# APM32L08x register map
File version: 1.0
CPU: CM0+ r0p0, little endian, MPU, no FPU, 4 interrupt priority bits
Registers are 32-bit, read-write, reset 0x0 unless marked. A register's access mark holds for its fields unless they carry their own. Offsets are from the block's base; [hi:lo] are bit positions; lines under a group give offsets from that group; {n}, {i} and the like mark numbered series.

## WWDT — Window watchdog
Base 0x40002C00
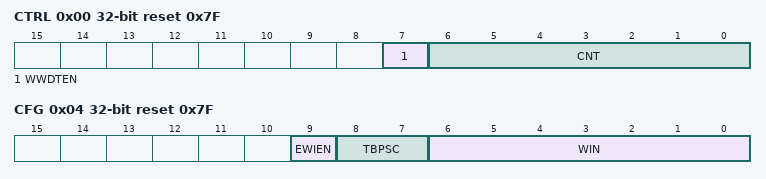
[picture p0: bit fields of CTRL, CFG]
0x00 CTRL reset 0x7F — Control register
  [7] WWDTEN — Activation bit
  [6:0] CNT — 7-bit counter
0x04 CFG reset 0x7F — Configuration register
  [9] EWIEN — Early wakeup interrupt
  [8:7] TBPSC — Timer base
  [6:0] WIN — 7-bit window value
0x08 STS — Status register
  [0] EWIFLG — Early wakeup interrupt flag

## TSC — Touch sensing controller
Base 0x40024000
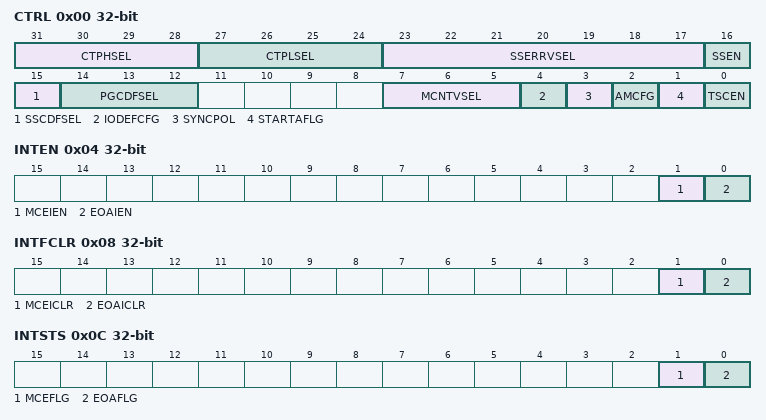
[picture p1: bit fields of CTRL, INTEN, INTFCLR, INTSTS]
0x00 CTRL — control register
  [31:28] CTPHSEL — Charge transfer pulse high
  [27:24] CTPLSEL — Charge transfer pulse low
  [23:17] SSERRVSEL — Spread spectrum deviation
  [16] SSEN — Spread spectrum enable
  [15] SSCDFSEL — Spread spectrum prescaler
  [14:12] PGCDFSEL — pulse generator prescaler
  [7:5] MCNTVSEL — Max count error value
  [4] IODEFCFG — I/O Default mode
  [3] SYNCPOL — Synchronization pin polarity
  [2] AMCFG — Acquisition mode
  [1] STARTAFLG — Start a new acquisition
  [0] TSCEN — Touch sensing controller enable
0x04 INTEN — interrupt enable register
  [1] MCEIEN — Max count error interrupt enable
  [0] EOAIEN — End of acquisition interrupt enable
0x08 INTFCLR — interrupt clear register
  [1] MCEICLR — Max count error interrupt clear
  [0] EOAICLR — End of acquisition interrupt clear
0x0C INTSTS ro — interrupt status register
  [1] MCEFLG — Max count error flag
  [0] EOAFLG — End of acquisition flag
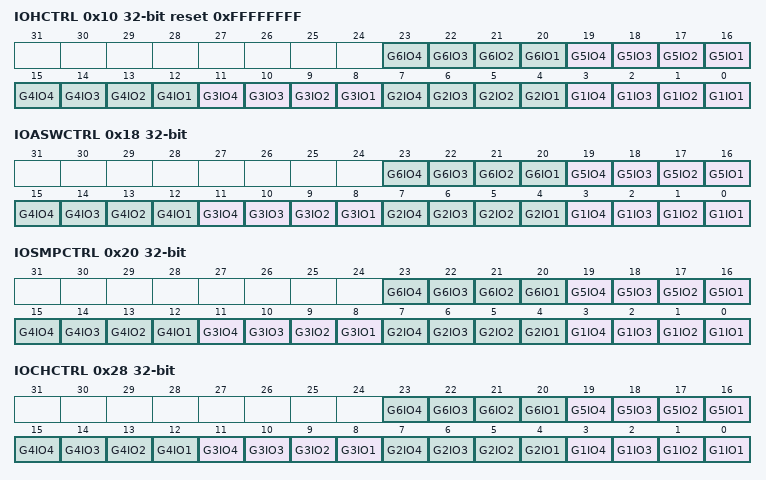
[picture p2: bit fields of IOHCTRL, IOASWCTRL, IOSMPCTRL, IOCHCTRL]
0x10 IOHCTRL reset 0xFFFFFFFF — I/O hysteresis control register
  [4n-1] G{n}IO4 (n=1..6) — G{n}IO4 Schmitt trigger hysteresis mode
  [4n-2] G{n}IO3 (n=1..6) — G{n}IO3 Schmitt trigger hysteresis mode
  [4n-3] G{n}IO2 (n=1..6) — G{n}IO2 Schmitt trigger hysteresis mode
  [4n-4] G{n}IO1 (n=1..6) — G{n}IO1 Schmitt trigger hysteresis mode
0x18 IOASWCTRL — I/O analog switch control register
  [4n-1] G{n}IO4 (n=1..6) — G{n}IO4 analog switch enable
  [4n-2] G{n}IO3 (n=1..6) — G{n}IO3 analog switch enable
  [4n-3] G{n}IO2 (n=1..6) — G{n}IO2 analog switch enable
  [4n-4] G{n}IO1 (n=1..6) — G{n}IO1 analog switch enable
0x20 IOSMPCTRL — I/O sampling control register
  [4n-1] G{n}IO4 (n=1..6) — G{n}IO4 sampling mode
  [4n-2] G{n}IO3 (n=1..6) — G{n}IO3 sampling mode
  [4n-3] G{n}IO2 (n=1..6) — G{n}IO2 sampling mode
  [4n-4] G{n}IO1 (n=1..6) — G{n}IO1 sampling mode
0x28 IOCHCTRL — I/O channel control register
  [4n-1] G{n}IO4 (n=1..6) — G{n}IO4 channel mode
  [4n-2] G{n}IO3 (n=1..6) — G{n}IO3 channel mode
  [4n-3] G{n}IO2 (n=1..6) — G{n}IO2 channel mode
  [4n-4] G{n}IO1 (n=1..6) — G{n}IO1 channel mode
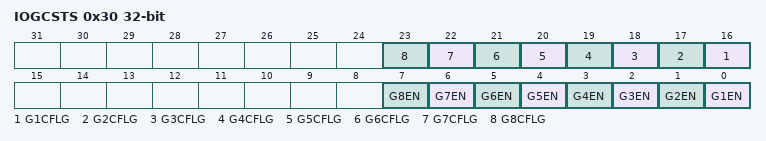
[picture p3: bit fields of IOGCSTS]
0x30 IOGCSTS access per field — I/O group control status register
  [n+15] G{n}CFLG ro (n=1..8) — Analog I/O group x status
  [n-1] G{n}EN rw (n=1..8) — Analog I/O group x enable
{0x30+4i} IOG{i}CNT ro (i=1..8) — I/O group x counter register
  [13:0] CNTVAL — Counter value

## LCD — Liquid crystal display controller
Base 0x40002400
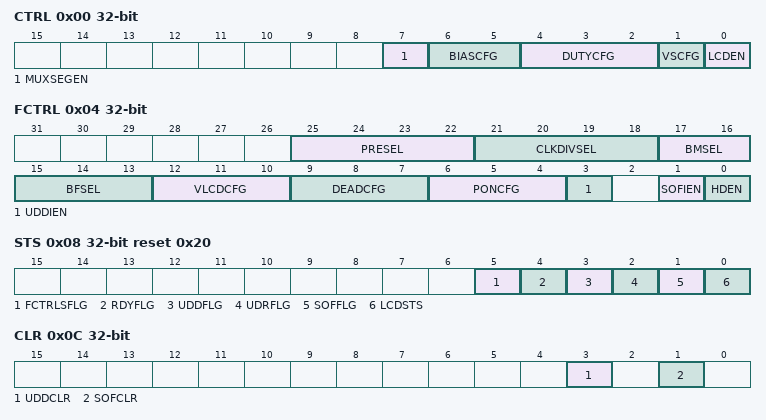
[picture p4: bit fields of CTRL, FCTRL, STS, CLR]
0x00 CTRL — control register
  [7] MUXSEGEN — Mux Segment Enable
  [6:5] BIASCFG — Bias Selector Configure
  [4:2] DUTYCFG — Duty Configure
  [1] VSCFG — Voltage Source Configure
  [0] LCDEN — LCD Controller Enable
0x04 FCTRL — frame control register
  [25:22] PRESEL — PS 16-bit prescaler Select
  [21:18] CLKDIVSEL — Clock Divider Select
  [17:16] BMSEL — Blink mode selection
  [15:13] BFSEL — Blink Frequency Select
  [12:10] VLCDCFG — VLCD Configure
  [9:7] DEADCFG — Dead Time Duration Configure
  [6:4] PONCFG — Pulse ON Duration Configure
  [3] UDDIEN — Update Display Done Interrupt Enable
  [1] SOFIEN — Start of Frame Interrupt Enable
  [0] HDEN — High Drive Enable
0x08 STS access per field reset 0x20 — status register
  [5] FCTRLSFLG ro — Frame Control Register Synchronization Flag
  [4] RDYFLG ro — Ready Flag
  [3] UDDFLG ro — Update Display Done Flag
  [2] UDRFLG rw — Update Display Request Flag
  [1] SOFFLG ro — Start of Frame Flag
  [0] LCDSTS ro — LCD enabled status
0x0C CLR access per field — clear register
  [3] UDDCLR rw — Update Display Done Flag Clear
  [1] SOFCLR ro — Start of Frame Flag Clear
{0x14+4i} DM{i} (i=0..15) — display memory
  [31:0] DATA — Display Data
